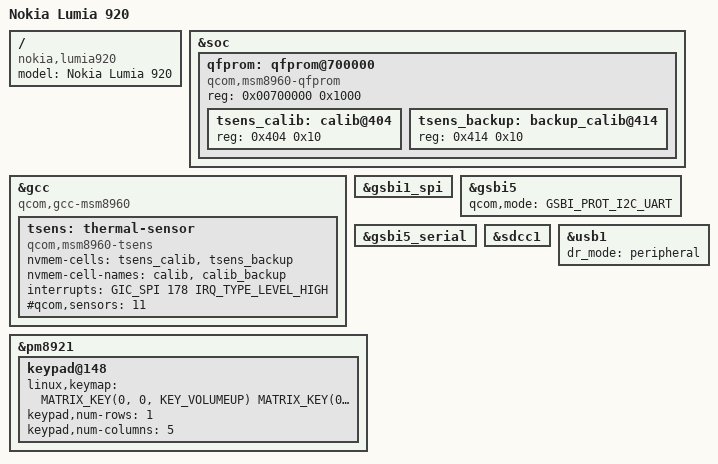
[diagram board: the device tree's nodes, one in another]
// SPDX-License-Identifier: GPL-2.0
#include <dt-bindings/input/input.h>

#include "qcom-msm8960.dtsi"
#include "pm8921.dtsi"

/ {
	model = "Nokia Lumia 920";
	compatible = "nokia,lumia920", "qcom,msm8960";
};

&soc {
    qfprom: qfprom@700000 {
        compatible = "qcom,msm8960-qfprom", "qcom,qfprom";
        reg = <0x00700000 0x1000>;

        #address-cells = <1>;
        #size-cells = <1>;
        ranges;

        tsens_calib: calib@404 {
            reg = <0x404 0x10>;
        };

        tsens_backup: backup_calib@414 {
            reg = <0x414 0x10>;
        };
    };
};

&gcc {
    compatible = "qcom,gcc-msm8960", "syscon";
    tsens: thermal-sensor {
        compatible = "qcom,msm8960-tsens";

        nvmem-cells = <&tsens_calib>, <&tsens_backup>;
        nvmem-cell-names = "calib", "calib_backup";

        interrupts = <GIC_SPI 178 IRQ_TYPE_LEVEL_HIGH>;
        interrupt-names = "uplow";

        #qcom,sensors = <11>;
        #thermal-sensor-cells = <1>;
    };
};

&gsbi1_spi {
	status = "okay";
};

&gsbi5 {
	qcom,mode = <GSBI_PROT_I2C_UART>;
	status = "okay";
};

&gsbi5_serial {
	status = "okay";
};

&pm8921 {
	keypad@148 {
		linux,keymap = <
			MATRIX_KEY(0, 0, KEY_VOLUMEUP)
			MATRIX_KEY(0, 1, KEY_VOLUMEDOWN)
			MATRIX_KEY(0, 2, KEY_CAMERA_FOCUS)
			MATRIX_KEY(0, 3, KEY_CAMERA)
			>;
		keypad,num-rows = <1>;
		keypad,num-columns = <5>;
	};
};

/* eMMC */
&sdcc1 {
	status = "okay";
};

// usb1
&usb1 {
    status = "okay";
    dr_mode = "peripheral";
};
